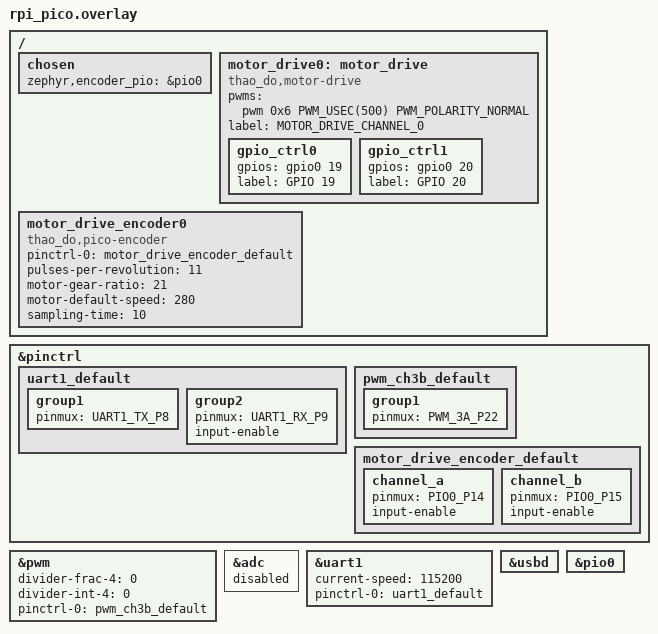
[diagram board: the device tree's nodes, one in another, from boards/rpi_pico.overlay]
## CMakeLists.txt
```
# SPDX-License-Identifier: Apache-2.0

cmake_minimum_required(VERSION 3.20.0)
find_package(Zephyr REQUIRED HINTS $ENV{ZEPHYR_BASE})
project(motor_control)

# Get the current build time
string(TIMESTAMP BUILD_TIME "%Y-%m-%d %H:%M:%S")

# Get the latest commit hash
execute_process(
    COMMAND git rev-parse --short HEAD
    WORKING_DIRECTORY ${CMAKE_SOURCE_DIR}
    OUTPUT_VARIABLE GIT_COMMIT_HASH
    OUTPUT_STRIP_TRAILING_WHITESPACE
)

# Pass the build time and commit hash as preprocessor definitions
add_definitions(-DBUILD_TIME="${BUILD_TIME}")
add_definitions(-DGIT_COMMIT_HASH="${GIT_COMMIT_HASH}")

# include(${ZEPHYR_BASE}/samples/subsys/usb/common/common.cmake)
zephyr_library_sources_ifdef(CONFIG_USB_COMMUNICATION src/usb.c)
zephyr_library_sources_ifdef(CONFIG_PID_CONTROLLER src/pid.c)
zephyr_library_sources_ifdef(CONFIG_FUZZY_CONTROLLER src/fuzzy_controller.c)
target_sources(app PRIVATE src/main.c)
```

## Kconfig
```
# Thao Do

source "samples/subsys/usb/common/Kconfig.sample_usbd"

source "Kconfig.zephyr"


config PID_CONTROLLER
    bool "ENABLE PID CONTROLLER"
    default n

config USB_COMMUNICATION
    bool "ENABLE USB COMMUNICATION"
    default n

config FUZZY_CONTROLLER
    bool "ENABLE FUZZY CONTROLLER"
    default n
```

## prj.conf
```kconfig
# Thao Do
CONFIG_GPIO=y
CONFIG_PWM=y
CONFIG_MOTOR_DRIVE=y
CONFIG_MOTOR_DRIVE_L298=y
CONFIG_SERIAL=y
# CONFIG_UART_CONSOLE=y
# CONFIG_LOG_BACKEND_UART=y
CONFIG_LOG=y
CONFIG_LOG_PROCESS_THREAD_STACK_SIZE=4096
CONFIG_LOG_BUFFER_SIZE=4096
CONFIG_CBPRINTF_FP_SUPPORT=y

# CONFIG_THREAD_RUNTIME_STATS=y
# CONFIG_SCHED_THREAD_USAGE_ALL=y
# CONFIG_SCHED_THREAD_USAGE_ANALYSIS=y

CONFIG_THREAD_NAME=y
# CONFIG_THREAD_ANALYZER=y
# CONFIG_THREAD_ANALYZER_USE_PRINTK=y
# CONFIG_THREAD_ANALYZER_AUTO=y
# CONFIG_THREAD_ANALYZER_AUTO_INTERVAL=5

CONFIG_USB_COMMUNICATION=y
CONFIG_PID_CONTROLLER=n
CONFIG_FUZZY_CONTROLLER=y
```

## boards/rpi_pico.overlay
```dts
&pinctrl {
	uart1_default: uart1_default {
		group1 {
			pinmux = <UART1_TX_P8>;
		};
		group2 {
			pinmux = <UART1_RX_P9>;
			input-enable;
		};
	};

	pwm_ch3b_default: pwm_ch3b_default {
		group1 {
			pinmux = <PWM_3A_P22>;
		};
	};

	motor_drive_encoder_default: motor_drive_encoder_default {
		channel_a {
			pinmux = <PIO0_P14>;
			input-enable;
		};
		channel_b {
			pinmux = <PIO0_P15>;
			input-enable;
		};
	};

};

&pwm {
	status = "okay";
	divider-frac-4 = <0>;
	divider-int-4 = <0>;
	pinctrl-0 = < &pwm_ch3b_default >;
	pinctrl-names = "default";
};

&adc {
	status = "disabled";
};

&uart1 {
	status = "okay";
	current-speed = < 115200 >;
	pinctrl-0 = <&uart1_default>;
	pinctrl-names = "default";
};

&usbd {
	status = "okay";
};

&pio0 {
	status = "okay";
};

// 25kHz PWM frequency
// 40000 ns = 0x9c40
// pwm channel = 9
// pwm flags = 0
/ {

	chosen {
		zephyr,encoder_pio = &pio0;
	};

	motor_drive0: motor_drive {
		compatible = "thao_do,motor-drive";
		status = "okay";
		pwms = <&pwm 0x6 PWM_USEC(500) PWM_POLARITY_NORMAL>; // PWM_POLARITY_INVERTED
		label = "MOTOR_DRIVE_CHANNEL_0";

		gpio_ctrl0: gpio_ctrl0 {
			gpios = <&gpio0 19 GPIO_ACTIVE_HIGH>;
			label = "GPIO 19";
		};

		gpio_ctrl1: gpio_ctrl1 {
			gpios = <&gpio0 20 GPIO_ACTIVE_HIGH>;
			label = "GPIO 20";
		};
	};

	motor_drive_encoder0: motor_drive_encoder0 {
		compatible = "thao_do,pico-encoder";
		status = "okay";
		pinctrl-0 = <&motor_drive_encoder_default>;
		pinctrl-names = "default";
		pulses-per-revolution = <11>;
		motor-gear-ratio = <21>;
		motor-default-speed = <280>;
		sampling-time = <10>; // ms
	};

};
```

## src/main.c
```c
/*
 * Copyright (c) 2023 Yonatan Schachter
 * Copyright (c) 2024 Thao Do
 *
 * SPDX-License-Identifier: Apache-2.0
 */

#include <zephyr/kernel.h>
#include <stdint.h>
#include <zephyr/drivers/motor_drive.h>
#include <zephyr/drivers/motor_drive_encoder.h>
#include "common.h"

#include <zephyr/logging/log.h>
LOG_MODULE_REGISTER(main, LOG_LEVEL_INF);

// Define the build time and commit hash if not already defined
#ifndef BUILD_TIME
#define BUILD_TIME "Unknown"
#endif

#ifndef GIT_COMMIT_HASH
#define GIT_COMMIT_HASH "Unknown"
#endif

#define MOTOR_SAMPLING_TIME_ZEPHYR_MS K_MSEC(MOTOR_SAMPLING_TIME_MS)
#define E_NORMALIZE (float)(1.0f/250.0f)
#define DELTA_E_NORMALIZE (float)(0.0001f)

static void timer_expiry_fnc(struct k_timer *timer);
static void speed_control(const struct device *drive, const struct device *encoder,
			  float set_point);
static void pos_control(const struct device *drive, const struct device *encoder, float set_point);

K_TIMER_DEFINE(pid_timer, timer_expiry_fnc, NULL);
K_SEM_DEFINE(pid_sem, 0, 1);
static float set_point = 0.0f;
static pi_controller controller;
static int current_direction = 0;
static fuzzy_controller f_controller;

static void timer_expiry_fnc(struct k_timer *timer)
{
	k_sem_give(&pid_sem);
}

static void timer_get_control_signal(struct k_timer *timer)
{
	const struct motor_drive_encoder_api *encoder_api = get_encoder_device()->api;
	float speed = 0.0f;

	encoder_api->get_speed(get_encoder_device(), &speed);

	// LOG_INF("current speed: %f", (double)speed);
	printk("%f\n", (double)speed);
}
K_TIMER_DEFINE(get_signal_timer, timer_get_control_signal, NULL);

float *get_set_point(void)
{
	return &set_point;
}

const struct device *get_encoder_device(void)
{
	return DEVICE_DT_GET(DT_NODELABEL(motor_drive_encoder0));
}

pi_controller *get_pi_controller(void)
{
	return &controller;
}

fuzzy_controller *get_fuzzy_controller(void)
{
	return &f_controller;
}

int main(void)
{
	LOG_INF("Booting to raspberry pi pico - bai tap lon 2024");
	LOG_INF("Build time: %s", BUILD_TIME);
	LOG_INF("Commit hash: %s", GIT_COMMIT_HASH);

	int rc;
	const struct device *motor_drive = DEVICE_DT_GET(DT_NODELABEL(motor_drive0));
	const struct device *encoder = DEVICE_DT_GET(DT_NODELABEL(motor_drive_encoder0));
	struct motor_driver_api *motor_driver_api;
	struct motor_drive_encoder_api *encoder_api;

	if (!device_is_ready(motor_drive)) {
		LOG_ERR("Motor drive device %s is not ready", motor_drive->name);
		return -ENODEV;
	}

	if (!device_is_ready(encoder)) {
		LOG_ERR("Encoder device %s is not ready", encoder->name);
		return -ENODEV;
	}

	motor_driver_api = (struct motor_driver_api *)motor_drive->api;
	encoder_api = (struct motor_drive_encoder_api *)encoder->api;

	rc = communication_init();
	if (rc) {
		LOG_ERR("failed to setup communication - rc = %d", rc);
		return rc;
	}

	rc = motor_driver_api->off(motor_drive, 0);
	if (rc) {
		LOG_ERR("failed to turn off motor - rc = %d", rc);
	}

	// k_timer_start(&get_signal_timer, K_SECONDS(2), K_SECONDS(2));
	k_timer_start(&pid_timer, MOTOR_SAMPLING_TIME_ZEPHYR_MS, MOTOR_SAMPLING_TIME_ZEPHYR_MS);
#if IS_ENABLED(CONFIG_PID_CONTROLLER)
	pi_init(get_pi_controller(), 0.1f, 0.01f, MOTOR_SAMPLING_TIME_MS);
#elif IS_ENABLED(CONFIG_FUZZY_CONTROLLER)
	fuzzy_control_init(get_fuzzy_controller(), E_NORMALIZE, DELTA_E_NORMALIZE, MOTOR_SAMPLING_TIME_MS);
#endif

	rc = motor_driver_api->on(motor_drive, 0, current_direction);
	if (rc) {
		LOG_ERR("failed to turn on motor - rc = %d", rc);
		return rc;
	}

	// speed range 70 rpm to 200 rpm
	*get_set_point() = 200.0f;

	while (1) {
		k_sem_take(&pid_sem, K_FOREVER);

		if (*is_speed_control()) {
			speed_control(motor_drive, encoder, *get_set_point());
		} else {
			// position control
			pos_control(motor_drive, encoder, *get_set_point());
		}
	}

	return 0;
}

float *get_control_speed()
{
	static float ava_speed;
	return &ava_speed;
}

static void speed_control(const struct device *drive, const struct device *encoder, float set_point)
{
	const struct motor_drive_encoder_api *encoder_api = encoder->api;
	const struct motor_driver_api *motor_driver_api = drive->api;
	int rc;
	static float speed[3];
	float output = 0.0f;

	speed[2] = speed[1];
	speed[1] = speed[0];

	rc = encoder_api->get_speed(encoder, &speed[0]);
	if (rc) {
		LOG_ERR("failed to get speed - rc = %d", rc);
		return;
	}

	float ava_speed = (speed[0] + speed[1] + speed[2]) / 3;
	*get_control_speed() = ava_speed;

#if IS_ENABLED(CONFIG_PID_CONTROLLER)
	output = pi_cal(get_pi_controller(), set_point, ava_speed);
#elif IS_ENABLED(CONFIG_FUZZY_CONTROLLER)
	output = fuzzy_control(get_fuzzy_controller(), set_point, ava_speed);
#else
	LOG_ERR("speed control is not supported");
	return;
#endif

	rc = motor_driver_api->set_voltage(drive, 0, output);
	if (rc) {
		LOG_ERR("failed to set speed - rc = %d", rc);
	}

	return;
}

static void pos_control(const struct device *drive, const struct device *encoder, float set_point)
{
	const struct motor_drive_encoder_api *encoder_api = encoder->api;
	const struct motor_driver_api *motor_driver_api = drive->api;
	int rc;
	float position = 0.0f;
	float speed = 0.0f;
	float output = 0.0f;
	static float pre_err = FLT_MAX;
	float err = 0;

	rc = encoder_api->get_position(encoder, &position);
	if (rc) {
		LOG_ERR("failed to get position - rc = %d", rc);
		return;
	}

	rc = encoder_api->get_speed(encoder, &speed);
	if (rc) {
		LOG_ERR("failed to get speed - rc = %d", rc);
		return;
	}

#if IS_ENABLED(CONFIG_PID_CONTROLLER)
	output = pi_pos_cal(get_pi_controller(), set_point, position);
#else
	LOG_ERR("pos control is not supported");
	return;
#endif

	err = set_point - position;
	err = err > 0 ? err : -err;

	if (err > pre_err) {
		// if error is increasing, we need to revert the motor direction
		// slow down the motor
		rc = motor_driver_api->set_voltage(drive, 0, 0);
		if (rc) {
			LOG_ERR("failed to set speed - rc = %d", rc);
			motor_driver_api->off(drive, 0);
		}

		if (speed < 5) {
			// before changing direction, we need to stop the motor
			current_direction = !current_direction;
			motor_driver_api->on(drive, 0, current_direction);
		}

	} else {
		// speed up the motor
		output = output > 0 ? output : -output;
		rc = motor_driver_api->set_voltage(drive, 0, output);
		if (rc) {
			LOG_ERR("failed to set speed - rc = %d", rc);
			motor_driver_api->off(drive, 0);
		}
	}

	pre_err = err;

	return;
}
```

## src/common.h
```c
/*
 * Copyright (c) 2024 Thao Do
 *
 * SPDX-License-Identifier: Apache-2.0
 */

#ifndef MOTOR_DRIVE_COMMON_H
#define MOTOR_DRIVE_COMMON_H

#include <zephyr/kernel.h>
#include <stdint.h>

#define COMMUNICATION_MAX_SIZE 32
#define COMMUNICATION_VERSION 1

// good for speed 20ms
#define MOTOR_SAMPLING_TIME_MS 20

enum communication_cmd {
    COMMUNICATION_GET_SPEED = 0,
    COMMUNICATION_SET_SPEED = 1,
    COMMNUICATION_GET_POSITION = 2,
    COMMUNICATION_SET_POSITION = 3,
    COMMUNICATION_SET_P = 4,
    COMMUNICATION_SET_I = 5,
    COMMUNICATION_SET_D = 6,
    COMMUNICATION_GET_SPEED_POSITION = 7,
    COMMUNICATION_SET_PI = 8,
};

struct common_header {
    uint8_t reserved;
    uint8_t ver;
    uint8_t cmd;
    uint8_t flags;
    uint8_t len;
    uint8_t crc;
} __packed;


struct common_message {
    struct common_header header;
    uint8_t payload[COMMUNICATION_MAX_SIZE - sizeof(struct common_header)];
} __packed;

/**
 * @brief Init communication thread
 *
 * @return int 0 if success, otherwise failed
 */
int communication_init(void);

typedef struct {
    float kp;         // Proportional gain
    float ki;         // Integral gain
    float kd;         // Derivative gain
    float ts;         // Sampling time
    float prev_error;  // Error at k-1
    float prev_output; // Control output at k-1
} pi_controller;


typedef struct {
    int32_t sample_time;
    float e_cofficient;
    float de_cofficient;
    float pre_e;
    float pre_output;
} fuzzy_controller;

// Initialize the PI controller
void pi_init(pi_controller *pi, float kp, float ki, float ts);

/** calulcate pwm output */
float pi_cal(pi_controller *pi, float setpoint, float measuredValue);

float *get_set_point(void);

pi_controller *get_pi_controller(void);

const struct device *get_encoder_device(void);

bool *is_speed_control(void);

float *get_control_speed(void);

float pi_pos_cal(pi_controller *pi, float setpoint, float measuredValue);


int32_t fuzzy_control_init(fuzzy_controller *fuzzy, float e_coff, float de_coff, int32_t sample_time);
float fuzzy_control(fuzzy_controller *ctrl, float set_point, float measured_value);

#endif
```

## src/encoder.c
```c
/**
 * Copyright (c) 2024 Thao Do
 *
 * SPDX-License-Identifier: Apache-2.0
 */

#include <stdint.h>
#include <zephyr/kernel.h>
#include <zephyr/logging/log.h>

#include "common.h"

LOG_MODULE_REGISTER(encoder, LOG_LEVEL_INF);

#define PULSES_PER_REVOLUTION (234)
#define MOTOR_DEFAULT_SPEED   (280)

// we wanna 2 GPIO to read the signal from encoder
// encoder parameters
// - motor 12V 280rpm
// - channel A and B have 11 pules per resolution
// - down ratio 21.3 : 1 -> that means we have 21.3 * 11 = 234.3 pulses per revolution
//                       -> 280rpm * 234.3 = 65604 pulses per minute
//                       -> 65604 / (60 * 1000) = 1.0934 pulses per ms
```

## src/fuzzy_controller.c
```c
// Thao Do 2025

#include <stdint.h>
#include <math.h>
#include <zephyr/logging/log.h>
#include <zephyr/kernel.h>

#include "common.h"

#define E_NORMALIZE (1/250.0f)
#define DELTA_E_NORMALIZE (0.0001f)
#define NUMBER_OF_RULES 25

static float fuzzy_rule_e[5][3] = {
    {-1, -0.6, -0.2},
    {-0.6, -0.2, 0},
    {-0.2, 0, 0.2},
    {0, 0.2, 0.6},
    {0.2, 0.6, 1}
};

static float fuzzy_rule_delta_e[5][3] = {
    {-1, -0.9, -0.5},
    {-0.9, -0.5, 0},
    {-0.5, 0, 0.5},
    {0, 0.5, 0.9},
    {0.5, 0.9, 1}
};

static float fuzzy_delta_u[] = {-1.0f, -0.95f, -0.6f, 0.0f, 0.6f, 0.95f, 1.0f};

static int32_t fuzzy_rule[NUMBER_OF_RULES][3] = {
    {0, 0, 0},
     {0, 1, 0},
     {0, 2, 1},
     {0, 3, 2},
     {0, 4, 1},
     {1, 0, 0},
     {1, 1, 1},
     {1, 2, 2},
     {1, 3, 3},
     {1, 4, 4},
     {2, 0, 1},
     {2, 1, 2},
     {2, 2, 3},
     {2, 3, 4},
     {2, 4, 5},
     {3, 0, 2},
     {3, 1, 3},
     {3, 2, 4},
     {3, 3, 5},
     {3, 4, 6},
    { 4, 0, 3},
    { 4, 1, 4},
    { 4, 2, 5},
    { 4, 3, 6},
    { 4, 4, 6},
};

static float triangular_mf(float x, float a, float b, float c)
{
    if (x < a || x > c) {
        return 0.0f;
    } else if (x <= b) {
        return (x - a) / (b - a);
    } else {
        return (c - x) / (c - b);
    }
}
static float trapezoidal_mf(float x, float a, float b, float c, float d)
{
    if (x < a || x > d) {
        return 0.0f;
    } else if (x <= b) {
        return (x - a) / (b - a);
    } else if (x <= c) {
        return 1.0f;
    } else {
        return (d - x) / (d - c);
    }
}

int32_t fuzzy_control_init(fuzzy_controller *fuzzy, float e_coff, float de_coff, int32_t sample_time)
{
    if (fuzzy == NULL) {
        return -1; // Error: fuzzy controller pointer is NULL
    }

    // Set the sample time
    fuzzy->sample_time = sample_time;

    // Set the coefficients
    fuzzy->e_cofficient = e_coff;
    fuzzy->de_cofficient = de_coff;

    // Initialize previous error and output
    fuzzy->pre_e = 0;
    fuzzy->pre_output = 0;

    return 0;
}


float fuzzy_control(fuzzy_controller *ctrl, float set_point, float measured_value)
{
    float e = set_point - measured_value;
    float du = 0;
    float delta_e = (e - ctrl->pre_e) / ctrl->sample_time;
    float numerator = 0;
    float denominator = 0;
    float e_membership[5] = { 0 };
    float delta_e_membership[5] = { 0 };

    ctrl->pre_e = e;

    e = e * ctrl->e_cofficient;
    delta_e = delta_e * ctrl->de_cofficient;

    for (uint32_t i = 0; i < ARRAY_SIZE(e_membership); i++) {
        if (i == 0) {
            e_membership[i] = trapezoidal_mf(e, -2, fuzzy_rule_e[i][0], fuzzy_rule_e[i][1], fuzzy_rule_e[i][2]);
            delta_e_membership[i] = trapezoidal_mf(delta_e, -2, fuzzy_rule_delta_e[i][0], fuzzy_rule_delta_e[i][1], fuzzy_rule_delta_e[i][2]);
        } else if (i == (ARRAY_SIZE(e_membership) - 1)) {
            e_membership[i] = trapezoidal_mf(e, fuzzy_rule_e[i][0], fuzzy_rule_e[i][1], fuzzy_rule_e[i][2], 2);
            delta_e_membership[i] = trapezoidal_mf(delta_e, fuzzy_rule_delta_e[i][0], fuzzy_rule_delta_e[i][1], fuzzy_rule_delta_e[i][2], 2);
        } else {
            e_membership[i] = triangular_mf(e, fuzzy_rule_e[i][0], fuzzy_rule_e[i][1], fuzzy_rule_e[i][2]);
            delta_e_membership[i] = triangular_mf(delta_e, fuzzy_rule_delta_e[i][0], fuzzy_rule_delta_e[i][1], fuzzy_rule_delta_e[i][2]);
        }
    }

    for (uint32_t i = 0; i < NUMBER_OF_RULES; i++) {
        int e_index = fuzzy_rule[i][0];
        int delta_e_index = fuzzy_rule[i][1];
        int output_index = fuzzy_rule[i][2];
        denominator += e_membership[e_index] * delta_e_membership[delta_e_index];
        numerator += e_membership[e_index] * delta_e_membership[delta_e_index] * fuzzy_delta_u[output_index];
    }

    if (denominator == 0) {
        du = 0;
    } else {
        du = numerator / denominator;
    }

    // update control signal
    float u = ctrl->pre_output + du;
    if (u >= 100.0f) {
        u = 100.0f;
    } else if (u <= 0.0f) {
        u = 0.0f;
    }
    ctrl->pre_output = u;
    return u;
}
```

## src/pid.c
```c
/*
 * Copyright (c) 2024 Thao Do
 *
 * SPDX-License-Identifier: Apache-2.0
 */

#include <stdint.h>
#include <math.h>
#include <zephyr/logging/log.h>

#include "common.h"

LOG_MODULE_REGISTER(pid);

// Initialize the PI controller
void pi_init(pi_controller *pi, float kp, float ki, float ts)
{
    pi->kp = kp;
    pi->ki = ki;
    pi->ts = ts;
    pi->prev_error = 0.0f;
    pi->prev_output = 0.0f;

    LOG_INF("PI controller initialized with kp = %f, ki = %f, ts = %f ms", (double)kp, (double)ki, (double)ts);
}

// Update the PI controller using z-transform
float pi_cal(pi_controller *pi, float setpoint, float measuredValue)
{
    // Calculate current error
    float error = setpoint - measuredValue;

    // Proportional term
    float p_out = pi->kp * error;

    // Integral term (discrete accumulation using z-transform)
    float i_out = pi->prev_output + pi->ki * (pi->ts * 0.001f) * error; // 0.001f is to convert ms to s

    // Control signal
    float output = p_out + i_out;
    if (output >= 100.0f) {
        output = 100.0f;
    }

    if (output <= 0.0f) {
        output = 0.0f;
    }

    // Update the previous states
    pi->prev_error = error;
    pi->prev_output = output;

    return output;
}

float pi_pos_cal(pi_controller *pi, float setpoint, float measuredValue)
{
    // Calculate current error
    float error = setpoint - measuredValue;

    // Proportional term
    float p_out = pi->kp * error;

    // Integral term (discrete accumulation using z-transform)
    float i_out = pi->prev_output + pi->ki * (pi->ts * 0.001f) * error; // 0.001f is to convert ms to s

    // Control signal
    float output = p_out + i_out;
    if (output >= 45.0f) {
        output = 45.0f;
    }

    if (output <= -45.0f) {
        output = -45.0f;
    }

    // Update the previous states
    pi->prev_error = error;
    pi->prev_output = output;

    return output;
}
```

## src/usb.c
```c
/*
 * Copyright (c) 2024 Thao Do
 *
 * SPDX-License-Identifier: Apache-2.0
 */

#include <stdint.h>
#include <zephyr/device.h>
#include <zephyr/drivers/uart.h>
#include <zephyr/kernel.h>
#include <zephyr/sys/atomic.h>
#include <string.h>
#include <zephyr/sys/crc.h>
#include <zephyr/drivers/motor_drive_encoder.h>

#include "common.h"

#include <zephyr/logging/log.h>
LOG_MODULE_REGISTER(communicate);

#define COMMUNICATION_SET_RESPONSE(msg, command, payload_len)                                      \
	do {                                                                                       \
		(msg)->header.ver = COMMUNICATION_VERSION;                                         \
		(msg)->header.cmd = command;                                                       \
		(msg)->header.len = payload_len + sizeof(struct common_header);                    \
		(msg)->header.crc = 0;                                                             \
	} while (0)

#define COMMUNICATION_CONVERT_FLOAT_TO_BYTE_ARRAY(f, b)                                            \
	do {                                                                                       \
		memcpy(b, &f, sizeof(float));                                                      \
	} while (0)

#define COMMUNICATION_CONVERT_BYTE_ARRAY_TO_FLOAT(b, f)                                            \
	do {                                                                                       \
		memcpy(&(f), (b), sizeof(float));                                                  \
	} while (0)

struct communicate_context {
	struct k_thread communicate_thread;
	K_KERNEL_STACK_MEMBER(stack, 1024);
	struct k_sem msg_in;
};

struct uart_message {
	struct common_message *msg;
	int index;
	atomic_t done;
	atomic_t busy;
	atomic_t error;
};

static void timer_wa_handler(struct k_timer *timer);
K_TIMER_DEFINE(timer_wa, timer_wa_handler, NULL);

static const struct device *uart1 = DEVICE_DT_GET(DT_NODELABEL(uart1));
static struct communicate_context uart_ctx;
static struct common_message recevice_msg_ = {0};
static struct common_message send_msg_ = {0};
static struct uart_message uart_recv_msg = {
	.msg = &recevice_msg_,
	.index = 0,
	.done = ATOMIC_INIT(0),
	.busy = ATOMIC_INIT(0),
	.error = ATOMIC_INIT(0),
};
static struct uart_message uart_send_msg = {
	.msg = &send_msg_,
	.index = 0,
	.done = ATOMIC_INIT(0),
	.busy = ATOMIC_INIT(0),
	.error = ATOMIC_INIT(0),
};

static inline struct uart_message *get_recv_msg(void)
{
	return &uart_recv_msg;
}

static inline struct uart_message *get_send_msg(void)
{
	return &uart_send_msg;
}

// after a period of time, if there is no new data, reset receiver buffer
static void timer_wa_handler(struct k_timer *timer)
{
	ARG_UNUSED(timer);
	if (atomic_get(&get_recv_msg()->busy) == 1 || atomic_get(&get_recv_msg()->done) == 1) {
		// buffer in use, do nothing
		return;
	} else {
		LOG_DBG("%s: reset receiver buffer", __func__);
		memset(get_recv_msg()->msg, 0, sizeof(struct common_message));
		atomic_set(&get_recv_msg()->busy, 0);
		atomic_set(&get_recv_msg()->done, 0);
		atomic_set(&get_recv_msg()->error, 0);
		get_recv_msg()->index = 0;
	}
}

static void uart_rx_handler(const struct device *uart_dev, void *user_data)
{
	struct communicate_context *usr_ctx = (struct communicate_context *)user_data;
	uint8_t data;
	int rc;

	if (uart_irq_rx_ready(uart_dev) != 1) {
		return;
	}

	if (atomic_get(&get_recv_msg()->busy) == 1 || atomic_get(&get_recv_msg()->done) == 1) {
		return;
	}

	rc = uart_fifo_read(uart_dev, &data, sizeof(data));
	if (!rc) {
		// no more data
		return;
	}

	LOG_DBG("uart recv: 0x%02x - index = %d", data, get_recv_msg()->index);

	*((char *)get_recv_msg()->msg + get_recv_msg()->index) = data;

	if (get_recv_msg()->index == 0) {
		// after 0.5 second, if there is no new data, reset receiver buffer
		k_timer_start(&timer_wa, K_MSEC(500), K_NO_WAIT);
	}
	get_recv_msg()->index++;
	if (get_recv_msg()->index >= sizeof(struct common_message)) {
		LOG_ERR("MCU-uart message is too long");
		atomic_set(&get_recv_msg()->error, 1);
		return;
	}

	// check if message is done
	if (get_recv_msg()->msg->header.len == get_recv_msg()->index) {
		atomic_set(&get_recv_msg()->done, 1);
		k_timer_stop(&timer_wa);
		k_sem_give(&usr_ctx->msg_in);
	}
}

static void uart_tx_handler(const struct device *uart_dev, void *user_data)
{
	int rc;
	static int priv_cnt = 0;

	if (uart_irq_tx_ready(uart_dev) <= 0) {
		return;
	}

	if (atomic_get(&get_send_msg()->error) == 1 || atomic_get(&get_send_msg()->done) == 0) {
		// note: in some cases, tx_read is still true but interrupt from another source
		LOG_DBG("error or not done");
		return;
	}

	if (get_send_msg()->index <= 0 && atomic_get(&get_send_msg()->done) == 1) {
		// complete to send message
		atomic_set(&get_send_msg()->done, 0);
		atomic_set(&get_send_msg()->busy, 0);
		// printk("total send %d bytes\n", priv_cnt);
		priv_cnt = 0;

		// release recv message buffer
		memset(get_recv_msg()->msg, 0, sizeof(struct common_message));
		atomic_set(&get_recv_msg()->busy, 0);
		atomic_set(&get_recv_msg()->done, 0);
		get_recv_msg()->index = 0;

		LOG_DBG("disable tx again");
		uart_irq_tx_disable(uart_dev);
		return;
	}

	// set buffer to busy state
	atomic_set(&get_send_msg()->busy, 1);
	rc = uart_fifo_fill(uart_dev, (char *)get_send_msg()->msg + priv_cnt, 1);
	if (rc <= 0) {
		LOG_WRN("could not send message (uart)");
		return;
	}

	priv_cnt++;
	get_send_msg()->index--;
}

/**
 * @brief UART interrupt callback
 *
 * @param uart_dev  uart device
 * @param user_data users's data
 */
static void uart_isr_cb(const struct device *uart_dev, void *user_data)
{
	while (uart_irq_is_pending(uart_dev) > 0 && uart_irq_update(uart_dev) > 0) {
		uart_rx_handler(uart_dev, user_data);
		uart_tx_handler(uart_dev, user_data);
	}
}

static int message_handler(struct common_message *msg, uint8_t len)
{
	struct common_message *recv_msg = (struct common_message *)msg;
	int rc = -ENODATA;
	float speed;
	float position;
	float p_cof;
	float i_cof;
	float d_cof;

	if (recv_msg->header.ver != COMMUNICATION_VERSION) {
		LOG_ERR("invalid version");
		return -EINVAL;
	}

	// check crc
	// uint8_t crc = crc8_ccitt(0, msg, len);
	// if (crc != recv_msg->header.crc) {
	// 	LOG_ERR("invalid crc");
	// 	return -EINVAL;
	// }

	// ((struct motor_drive_encoder_api *)get_encoder_device()->api)
	// 	->get_speed(get_encoder_device(), &speed);
	speed = *get_control_speed();
	((struct motor_drive_encoder_api *)get_encoder_device()->api)
		->get_position(get_encoder_device(), &position);

	switch (recv_msg->header.cmd) {
	case COMMUNICATION_GET_SPEED:
		COMMUNICATION_SET_RESPONSE(get_send_msg()->msg, COMMUNICATION_GET_SPEED,
					   sizeof(float));
		memcpy(get_send_msg()->msg->payload, &speed, sizeof(float));
		get_send_msg()->index = get_send_msg()->msg->header.len;
		LOG_DBG("get speed");
		rc = 0;
		break;
	case COMMUNICATION_SET_SPEED:
		COMMUNICATION_CONVERT_BYTE_ARRAY_TO_FLOAT(recv_msg->payload, speed);
		*get_set_point() = speed;
		*is_speed_control() = true;
		LOG_INF("set speed %f", (double)speed);
		break;
	case COMMNUICATION_GET_POSITION:
		COMMUNICATION_SET_RESPONSE(get_send_msg()->msg, COMMNUICATION_GET_POSITION,
					   sizeof(float));
		memcpy(get_send_msg()->msg->payload, &position, sizeof(float));
		get_send_msg()->index = get_send_msg()->msg->header.len;
		LOG_DBG("get position");
		rc = 0;
		break;
	case COMMUNICATION_SET_POSITION:
		COMMUNICATION_CONVERT_BYTE_ARRAY_TO_FLOAT(recv_msg->payload, position);
		*get_set_point() = position;
		*is_speed_control() = false;
		((struct motor_drive_encoder_api *)get_encoder_device()->api)->reset_count(get_encoder_device());
		LOG_INF("set position %f", (double)position);
		break;
	case COMMUNICATION_SET_P:
		COMMUNICATION_CONVERT_BYTE_ARRAY_TO_FLOAT(recv_msg->payload, p_cof);
		get_pi_controller()->kp = p_cof;
		LOG_INF("set P %f", (double)p_cof);
		break;
	case COMMUNICATION_SET_I:
		COMMUNICATION_CONVERT_BYTE_ARRAY_TO_FLOAT(recv_msg->payload, i_cof);
		get_pi_controller()->ki = i_cof;
		LOG_INF("set I %f", (double)i_cof);
		break;
	case COMMUNICATION_SET_D:
		COMMUNICATION_CONVERT_BYTE_ARRAY_TO_FLOAT(recv_msg->payload, d_cof);
		get_pi_controller()->kd = d_cof;
		LOG_INF("set D %f", (double)d_cof);
		break;
	case COMMUNICATION_GET_SPEED_POSITION:
		COMMUNICATION_SET_RESPONSE(get_send_msg()->msg, COMMUNICATION_GET_SPEED_POSITION,
					   sizeof(float) * 2);
		memcpy(get_send_msg()->msg->payload, &speed, sizeof(speed));
		memcpy(get_send_msg()->msg->payload + sizeof(speed), &position, sizeof(position));
		get_send_msg()->index = get_send_msg()->msg->header.len;
		rc = 0;
		break;
	case COMMUNICATION_SET_PI:
		COMMUNICATION_CONVERT_BYTE_ARRAY_TO_FLOAT(recv_msg->payload, p_cof);
		COMMUNICATION_CONVERT_BYTE_ARRAY_TO_FLOAT((recv_msg->payload + 4), i_cof);
		if (p_cof < 0 || i_cof < 0 || p_cof > 100 || i_cof > 10) {
			LOG_ERR("invalid PI value");
			return -EINVAL;
		}
		get_pi_controller()->kp = p_cof;
		get_pi_controller()->ki = i_cof;
		LOG_INF("set PI %f %f", (double)p_cof, (double)i_cof);
		break;
	default:
		LOG_DBG("invalid command");
		return -EINVAL;
	}

	return rc;
}

static int setup_uart(const struct device *uart, void *user_data)
{
	char data;

	if (!device_is_ready(uart)) {
		return -EIO;
	}

	uart_irq_rx_disable(uart);
	uart_irq_tx_disable(uart);
	// flush data
	while (uart_fifo_read(uart, &data, sizeof(data)) > 0) {
		// do nothing
		continue;
	}
	uart_irq_callback_user_data_set(uart, uart_isr_cb, user_data);
	uart_irq_rx_enable(uart);

	return 0;
}

bool *is_speed_control(void)
{
	static bool is_speed = true;
	return &is_speed;
}

static void uart_thread(void *arg1, void *arg2, void *arg3)
{
	ARG_UNUSED(arg3);

	struct communicate_context *thread_ctx = (struct communicate_context *)arg1;
	const struct device *uart = (const struct device *)arg2;
	int rc;

	do {
		k_sem_take(&thread_ctx->msg_in, K_FOREVER);
		LOG_DBG("%s: new msg in", __func__);

		// set recv message to busy state
		atomic_set(&get_recv_msg()->busy, 1);

		rc = message_handler(get_recv_msg()->msg, get_recv_msg()->msg->header.len);
		if (!rc) {
			// printk("response %d bytes\n", get_send_msg()->index);
			atomic_set(&get_send_msg()->done, 1);
			uart_irq_tx_enable(uart);
		} else {
			// release recv message buffer
			// memset(get_recv_msg()->msg, 0, sizeof(struct common_message));
			atomic_set(&get_recv_msg()->busy, 0);
			atomic_set(&get_recv_msg()->done, 0);
			get_recv_msg()->index = 0;
		}

	} while (true);

	return;
}

int communication_init(void)
{
	LOG_INF("init communicate thread");

	k_sem_init(&uart_ctx.msg_in, 0, 1);

	setup_uart(uart1, &uart_ctx);

	k_thread_create(&uart_ctx.communicate_thread, uart_ctx.stack,
			K_KERNEL_STACK_SIZEOF(uart_ctx.stack), uart_thread, &uart_ctx,
			(void *)uart1, NULL, K_LOWEST_THREAD_PRIO, 0, K_NO_WAIT);
	k_thread_name_set(&uart_ctx.communicate_thread, "uart_thread");

	return 0;
}
```
